# RESETSAFE register map
Registers from a debugger description file.
Registers are 32-bit, read-only, no defined reset value unless marked. A register's access mark holds for its fields unless they carry their own. Addresses are absolute; registers are grouped by the start of their names; lines under a group give offsets from that group; [hi:lo] are bit positions; {n}, {i} and the like mark numbered series; 'fields as' and 'values as' point back to an identical list; <NAME> marks a mode.

## SFR
0x51006000 rResetLoadCount access not given
  [15:0] LoadCount
0x51006004 rResetCurrentCount
  [15:0] CurrentCount
0x51006008 rResetStatusInt0
  [0] StatusInt0
0x5100600C rResetStatusInt1
  [0] StatusInt1
0x51006010 rResetClearInt
  [0] ClearInt
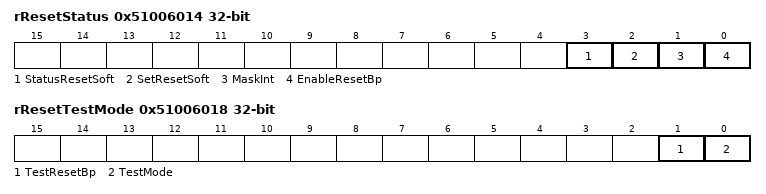
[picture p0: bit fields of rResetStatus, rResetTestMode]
0x51006014 rResetStatus access not given
  [3] StatusResetSoft, [2] SetResetSoft, [1] MaskInt, [0] EnableResetBp
0x51006018 rResetTestMode access not given
  [1] TestResetBp, [0] TestMode
